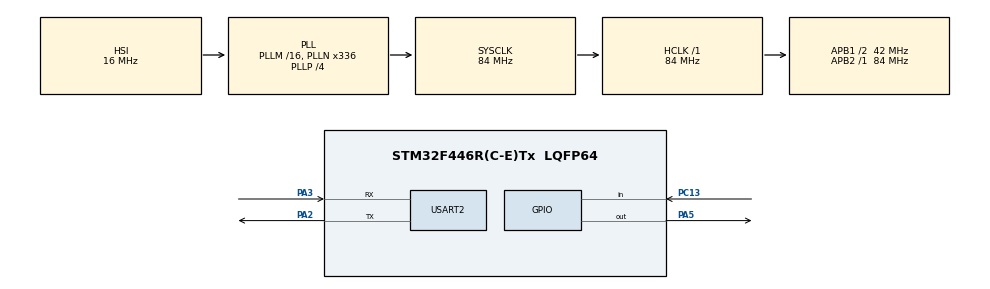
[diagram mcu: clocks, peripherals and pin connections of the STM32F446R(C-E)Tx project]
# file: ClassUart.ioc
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Dma.Request0=USART2_RX
Dma.USART2_RX.0.Direction=DMA_PERIPH_TO_MEMORY
Dma.USART2_RX.0.FIFOMode=DMA_FIFOMODE_DISABLE
Dma.USART2_RX.0.Instance=DMA1_Stream5
Dma.USART2_RX.0.MemDataAlignment=DMA_MDATAALIGN_BYTE
Dma.USART2_RX.0.MemInc=DMA_MINC_ENABLE
Dma.USART2_RX.0.Mode=DMA_NORMAL
Dma.USART2_RX.0.PeriphDataAlignment=DMA_PDATAALIGN_BYTE
Dma.USART2_RX.0.PeriphInc=DMA_PINC_DISABLE
Dma.USART2_RX.0.Priority=DMA_PRIORITY_LOW
Mcu.Family=STM32F4
Mcu.Name=STM32F446R(C-E)Tx
Mcu.Package=LQFP64
NVIC.DMA1_Stream5_IRQn=true\:0\:0\:false\:false\:true\:false\:true
NVIC.PriorityGroup=NVIC_PRIORITYGROUP_0
NVIC.USART2_IRQn=true\:0\:0\:false\:false\:true\:true\:true
PA13.GPIO_Label=TMS
PA13.Signal=SYS_JTMS-SWDIO
PA14.GPIO_Label=TCK
PA14.Signal=SYS_JTCK-SWCLK
PA2.Mode=Asynchronous
PA2.Signal=USART2_TX
PA3.Mode=Asynchronous
PA3.Signal=USART2_RX
PA5.Signal=GPIO_Output
PB3.GPIO_Label=SWO
PB3.Signal=SYS_JTDO-SWO
PC13.Signal=GPIO_Input
PC14-OSC32_IN.Signal=RCC_OSC32_IN
PC15-OSC32_OUT.Signal=RCC_OSC32_OUT
PH0-OSC_IN.Signal=RCC_OSC_IN
PH1-OSC_OUT.Signal=RCC_OSC_OUT
ProjectManager.HeapSize=0x200
ProjectManager.StackSize=0x400
ProjectManager.TargetToolchain=STM32CubeIDE
RCC.AHBFreq_Value=84000000
RCC.APB1CLKDivider=RCC_HCLK_DIV2
RCC.APB1Freq_Value=42000000
RCC.APB1TimFreq_Value=84000000
RCC.APB2Freq_Value=84000000
RCC.APB2TimFreq_Value=84000000
RCC.CortexFreq_Value=84000000
RCC.FLatency-AdvancedSettings=FLASH_LATENCY_2
RCC.HCLKFreq_Value=84000000
RCC.HSE_VALUE=8000000
RCC.HSI_VALUE=16000000
RCC.LSE_VALUE=32768
RCC.PLLN=336
RCC.PLLP=RCC_PLLP_DIV4
RCC.SYSCLKFreq_VALUE=84000000
RCC.SYSCLKSource=RCC_SYSCLKSOURCE_PLLCLK
RCC.USBFreq_Value=168000000
RCC.VCOOutputFreq_Value=336000000
USART2.VirtualMode=VM_ASYNC
board=NUCLEO-F446RE

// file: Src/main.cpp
/* USER CODE BEGIN Header */
/**
  ******************************************************************************
  * @file           : main.c
  * @brief          : Main program body
  ******************************************************************************
  * @attention
  *
  * <h2><center>&copy; Copyright (c) 2020 STMicroelectronics.
  * All rights reserved.</center></h2>
  *
  * This software component is licensed by ST under BSD 3-Clause license,
  * the "License"; You may not use this file except in compliance with the
  * License. You may obtain a copy of the License at:
  *                        opensource.org/licenses/BSD-3-Clause
  *
  ******************************************************************************
  */
/* USER CODE END Header */

#include "main.h"
#include "stm32f4xx_hal.h"
#include "stm32f4xx_hal_uart.h"
#include "stm32f4xx_hal_tim.h"
#include "stm32f4xx_hal_dma.h"
#include "cstdint"
#include <ClassUartTest.h>
#include "string.h"

/* USER CODE BEGIN PTD */
UART_HandleTypeDef huart2;
/* USER CODE END PTD */

void SystemClock_Config(void);
void MX_GPIO_Init(void);
void MX_USART2_UART_Init(void);

int main(void)
{

  /* MCU Configuration--------------------------------------------------------*/

  /* Reset of all peripherals, Initializes the Flash interface and the Systick. */
  HAL_Init();

  /* Configure the system clock */
  SystemClock_Config();

  /* Initialize all configured peripherals */

  MX_GPIO_Init();
  MX_USART2_UART_Init();
  //MX_DMA_Init();
  //MX_SPI1_Init();

  uint8_t myTxData[14]= "Hello World\r\n";
  uint8_t myRxData[1];
  ClassUartTest uartTest1(huart2);
  /* USER CODE END 2 */
  /* Infinite loop */
  while (1)
  {
	  //TODO: Implement the following program using uartTest1 variable:
	  //		Send some string (e.g. "Hello World") when you receive a specific character (e.g. 'c').

	  if (uartTest1.receiveMessage(myRxData, sizeof(myRxData), 100) == true)	//TODO-AKOS: You used an invalid size for myRxData.
	  {

	  }
	  HAL_Delay(500);
  }
}

void SystemClock_Config(void)
{
  RCC_OscInitTypeDef RCC_OscInitStruct = {0};
  RCC_ClkInitTypeDef RCC_ClkInitStruct = {0};

  /** Configure the main internal regulator output voltage
  */
  __HAL_RCC_PWR_CLK_ENABLE();
  __HAL_PWR_VOLTAGESCALING_CONFIG(PWR_REGULATOR_VOLTAGE_SCALE3);
  /** Initializes the CPU, AHB and APB busses clocks
  */
  RCC_OscInitStruct.OscillatorType = RCC_OSCILLATORTYPE_HSI;
  RCC_OscInitStruct.HSIState = RCC_HSI_ON;
  RCC_OscInitStruct.HSICalibrationValue = RCC_HSICALIBRATION_DEFAULT;
  RCC_OscInitStruct.PLL.PLLState = RCC_PLL_ON;
  RCC_OscInitStruct.PLL.PLLSource = RCC_PLLSOURCE_HSI;
  RCC_OscInitStruct.PLL.PLLM = 16;
  RCC_OscInitStruct.PLL.PLLN = 336;
  RCC_OscInitStruct.PLL.PLLP = RCC_PLLP_DIV4;
  RCC_OscInitStruct.PLL.PLLQ = 2;
  RCC_OscInitStruct.PLL.PLLR = 2;
  if (HAL_RCC_OscConfig(&RCC_OscInitStruct) != HAL_OK)
  {
    Error_Handler();
  }
  /** Initializes the CPU, AHB and APB busses clocks
  */
  RCC_ClkInitStruct.ClockType = RCC_CLOCKTYPE_HCLK|RCC_CLOCKTYPE_SYSCLK
                              |RCC_CLOCKTYPE_PCLK1|RCC_CLOCKTYPE_PCLK2;
  RCC_ClkInitStruct.SYSCLKSource = RCC_SYSCLKSOURCE_PLLCLK;
  RCC_ClkInitStruct.AHBCLKDivider = RCC_SYSCLK_DIV1;
  RCC_ClkInitStruct.APB1CLKDivider = RCC_HCLK_DIV2;
  RCC_ClkInitStruct.APB2CLKDivider = RCC_HCLK_DIV1;

  if (HAL_RCC_ClockConfig(&RCC_ClkInitStruct, FLASH_LATENCY_2) != HAL_OK)
  {
    Error_Handler();
  }
}

void MX_GPIO_Init(void)
{
  GPIO_InitTypeDef GPIO_InitStruct = {0};

  /* GPIO Ports Clock Enable */
  __HAL_RCC_GPIOC_CLK_ENABLE();
  __HAL_RCC_GPIOH_CLK_ENABLE();
  __HAL_RCC_GPIOA_CLK_ENABLE();
  __HAL_RCC_GPIOB_CLK_ENABLE();

  /*Configure GPIO pin Output Level */
  HAL_GPIO_WritePin(GPIOA, GPIO_PIN_5, GPIO_PIN_RESET);

  /*Configure GPIO pin : PC13 */
  GPIO_InitStruct.Pin = GPIO_PIN_13;
  GPIO_InitStruct.Mode = GPIO_MODE_INPUT;
  GPIO_InitStruct.Pull = GPIO_NOPULL;
  HAL_GPIO_Init(GPIOC, &GPIO_InitStruct);

  /*Configure GPIO pin : PA5 */
  GPIO_InitStruct.Pin = GPIO_PIN_5;
  GPIO_InitStruct.Mode = GPIO_MODE_OUTPUT_PP;
  GPIO_InitStruct.Pull = GPIO_NOPULL;
  GPIO_InitStruct.Speed = GPIO_SPEED_FREQ_LOW;
  HAL_GPIO_Init(GPIOA, &GPIO_InitStruct);

}

void Error_Handler(void)
{
	/* USER CODE BEGIN Error_Handler_Debug */
	while(1);
	/* USER CODE END Error_Handler_Debug */
}

/************************ (C) COPYRIGHT STMicroelectronics *****END OF FILE****/
